# ADuCM320 register map
Vendor: Analog Devices Inc.; Series: ARMCM3; File version: 1.1
CPU: CM3 r2p1, little endian, no MPU, no FPU, 3 interrupt priority bits
Registers are 16-bit, read-write, no defined reset value unless marked. A register's access mark holds for its fields unless they carry their own. Offsets are from the block's base; [hi:lo] are bit positions; {n}, {i} and the like mark numbered series.

## DMA — Direct Memory Access
Base 0x40010000
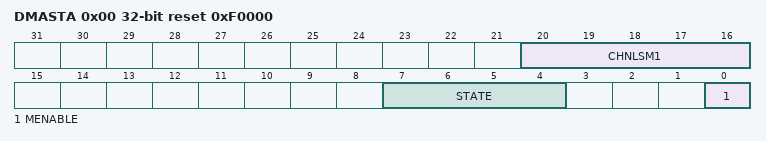
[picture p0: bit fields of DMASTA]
0x00 DMASTA 32-bit ro reset 0xF0000 (reset mask 0x0) — DMA Status
  [20:16] CHNLSM1 range 0x00000000..0x0000001F — Number of available DMA channels minus 1
  [7:4] STATE range 0x00000000..0x0000000F — Current state of DMA controller
  [0] MENABLE range 0x00000000..0x00000001 — Enable status of the controller
0x04 DMACFG 32-bit wo — DMA Configuration
  [0] MENABLE range 0x00000000..0x00000001 — Controller enable
0x08 DMAPDBPTR 32-bit — DMA channel primary control data base pointer
  [31:0] CTRLBASEPTR range 0x00000000..0xFFFFFFFF — Pointer to the base address of the primary data structure
0x0C DMAADBPTR 32-bit ro reset 0x100 (reset mask 0x0) — DMA channel alternate control data base pointer
  [31:0] ALTCBPTR range 0x00000000..0xFFFFFFFF — Base address of the alternate data structure
0x14 DMASWREQ 32-bit wo — DMA channel software request
  [13:0] CHSWREQ range 0x00000000..0x00003FFF — Generate software request
0x20 DMARMSKSET 32-bit — DMA channel request mask set
  [13:0] CHREQMSET range 0x00000000..0x00003FFF — Mask requests from DMA channels
0x24 DMARMSKCLR 32-bit wo — DMA channel request mask clear
  [13:0] CHREQMCLR range 0x00000000..0x00003FFF — Clear REQ_MASK_SET bits in DMARMSKSET
0x28 DMAENSET 32-bit — DMA channel enable set
  [13:0] CHENSET range 0x00000000..0x00003FFF — Enable DMA channels
0x2C DMAENCLR 32-bit wo — DMA channel enable clear
  [13:0] CHENCLR range 0x00000000..0x00003FFF — Disable DMA channels
0x30 DMAALTSET 32-bit — DMA channel primary-alternate set
  [13:0] CHPRIALTSET range 0x00000000..0x00003FFF — Control struct status / select alt struct
0x34 DMAALTCLR 32-bit wo — DMA channel primary-alternate clear
  [13:0] CHPRIALTCLR range 0x00000000..0x00003FFF — Select primary data struct
0x38 DMAPRISET 32-bit — DMA channel priority set
  [13:0] CHPRISET range 0x00000000..0x00003FFF — Configure channel for high priority
0x3C DMAPRICLR 32-bit wo — DMA channel priority clear
  [13:0] CHPRICLR range 0x00000000..0x00003FFF — Configure channel for default priority level
0x4C DMAERRCLR 32-bit — DMA Per Channel Bus Error
  [13:0] ERRCLR range 0x00000000..0x00003FFF — Bus error status
0x800 DMABSSET 32-bit — DMA channel bytes swap enable set
  [13:0] CHBSWAPSET range 0x00000000..0x00003FFF — Byte swap status
0x804 DMABSCLR 32-bit wo — DMA channel bytes swap enable clear
  [13:0] CHBSWAPCLR range 0x00000000..0x00003FFF — Disable byte swap

## GPIO0 — General Purpose Input Output 0
Base 0x40020000
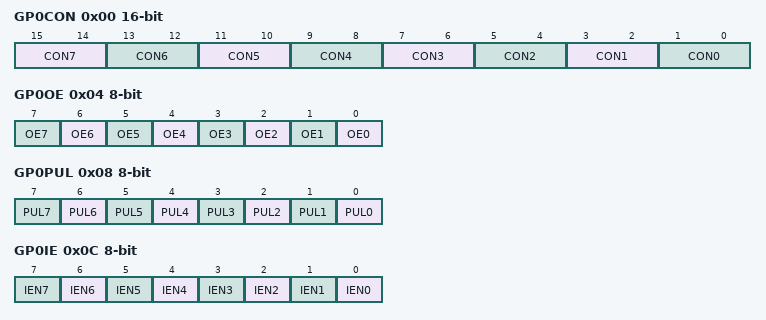
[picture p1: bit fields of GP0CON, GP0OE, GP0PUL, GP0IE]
0x00 GP0CON — GPIO Port 0 configuration
  [15:14] CON7 — p0.7 configuration bits
    0=GPIO; 1=I2C1SDA; 3=PLAO3
  [13:12] CON6 — p0.6 configuration bits
    0=GPIO; 1=I2C1SCL; 3=PLAO2
  [11:10] CON5 — p0.5 configuration bits
    0=GPIO; 1=I2C0SDA; 3=PLAO1
  [9:8] CON4 — p0.4 configuration bits
    0=GPIO; 1=I2CSCL (I2C0 SCL); 3=PLAO0
  [7:6] CON3 — p0.3 configuration bits
    0=GPIOIRQ0; 1=SPI0CS; 2=PLACLK0; 3=PLAI3
  [5:4] CON2 — p0.2 configuration bits
    0=GPIO; 1=SPI0MOSI; 3=PLAI2
  [3:2] CON1 — p0.1 configuration bits
    0=GPIO; 1=SIP0MISO (SPI0 MISO); 3=PLAI1
  [1:0] CON0 — p0.0 configuration bits
    0=GPIO; 1=SPI0SCLK; 3=PLAI0
0x04 GP0OE 8-bit — GPIO Port 0 output enable
  [all] fields
    0=DIS; 1=EN
  [n] OE{n} (n=0..7) — Pin output drive enable
0x08 GP0PUL 8-bit — GPIO Port 0 pullup enable
  [all] fields
    0=DIS; 1=EN
  [n] PUL{n} (n=0..7) — Pin Pull up enable
0x0C GP0IE 8-bit — GPIO Port 0 input path enable
  [all] fields
    0=DIS; 1=EN
  [n] IEN{n} (n=0..7) — Input path enable
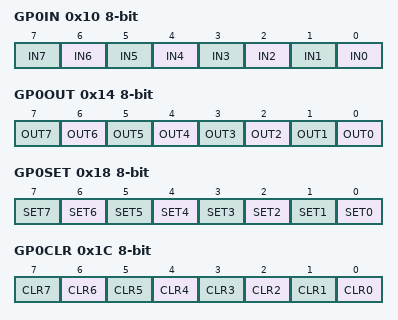
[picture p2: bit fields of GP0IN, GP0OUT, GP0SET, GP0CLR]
0x10 GP0IN 8-bit ro — GPIO Port 0 registered data input
  [all] fields
    0=LOW; 1=HIGH
  [n] IN{n} (n=0..7) — Registered data input
0x14 GP0OUT 8-bit — GPIO Port 0 data output
  [all] fields
    0=LOW; 1=HIGH
  [n] OUT{n} (n=0..7) — Data out
0x18 GP0SET 8-bit wo — GPIO Port 0 data out set
  [all] fields
    1=SET
  [n] SET{n} (n=0..7) — Set the output high.
0x1C GP0CLR 8-bit wo — GPIO Port 0 data out clear
  [all] fields
    1=CLR
  [n] CLR{n} (n=0..7) — Set the output low.
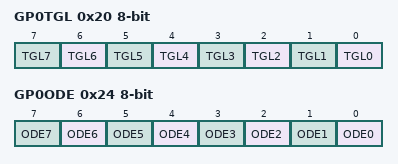
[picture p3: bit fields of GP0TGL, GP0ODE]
0x20 GP0TGL 8-bit wo — GPIO Port 0 pin toggle
  [all] fields
    1=TGL
  [n] TGL{n} (n=0..7) — Toggle the output of the port pin
0x24 GP0ODE 8-bit — GPIO Port 0 open drain enable
  [all] fields
    0=DIS; 1=EN
  [n] ODE{n} (n=0..7) — Open drain enable
